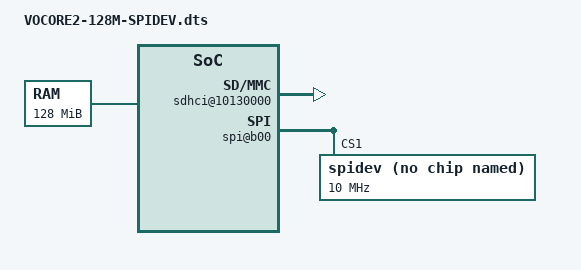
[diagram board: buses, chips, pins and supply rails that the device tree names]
/dts-v1/;

/include/ "VOCORE2.dtsi"
/{
	memory@0 {
		device_type = "memory";
		reg = <0x0 0x8000000>;
	};
	sdhci@10130000 {
		mediatek,cd-poll;
		status = "okay";
	};
	palmbus@10000000 {
		spi@b00 {
			spidev@1 {
				compatible = "linux,spidev";
				spi-max-frequency = <10000000>;
				reg = <1 0>;
			};
		};
	};
};
